# FM33FG0XXA register map
File version: 1.0
CPU: SC000 r1p0, little endian, MPU, no FPU, 3 interrupt priority bits
Registers are 32-bit, read-only, reset 0x0 unless marked. A register's access mark holds for its fields unless they carry their own. Offsets are from the block's base; [hi:lo] are bit positions; {n}, {i} and the like mark numbered series.

## CMU — CMU module information
Base 0x40002400
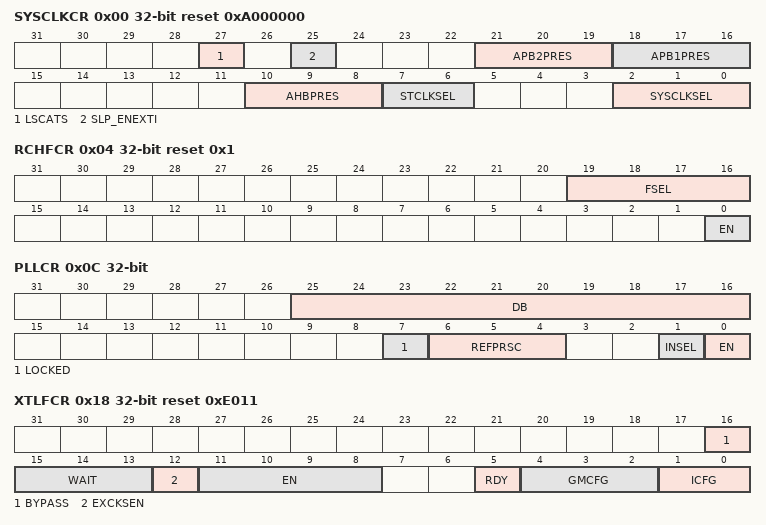
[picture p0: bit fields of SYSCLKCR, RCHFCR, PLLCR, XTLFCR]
0x00 SYSCLKCR rw reset 0xA000000 — System Clock Control Register
  [27] LSCATS — LSCATS field description
  [25] SLP_ENEXTI — SLP_ENEXTI field description
  [21:19] APB2PRES — APB2PRES field description
  [18:16] APB1PRES — APB1PRES field description
  [10:8] AHBPRES — AHBPRES field description
  [7:6] STCLKSEL — STCLKSEL field description
  [2:0] SYSCLKSEL — SYSCLKSEL field description
0x04 RCHFCR rw reset 0x1 — RCHF Control Register
  [19:16] FSEL — FSEL field description
  [0] EN — EN field description
0x08 RCHFTR rw — RCHF Trim Register
  [7:0] TRIM — TRIM field description
0x0C PLLCR access per field — PLL Control Register
  [25:16] DB rw — DB field description
  [7] LOCKED ro — LOCKED field description
  [6:4] REFPRSC rw — REFPRSC field description
  [1] INSEL rw — INSEL field description
  [0] EN rw — EN field description
0x14 RCLPTR rw — RCLP Trim Register
  [7:0] TRIM — TRIM field description
0x18 XTLFCR access per field reset 0xE011 — XTLF Control Register
  [16] BYPASS rw — BYPASS field description
  [15:13] WAIT rw — WAIT field description
  [12] EXCKSEN rw — EXCKSEN field description
  [11:8] EN rw — EN field description
  [5] RDY ro — RDY field description
  [4:2] GMCFG rw — GMCFG field description
  [1:0] ICFG rw — ICFG field description
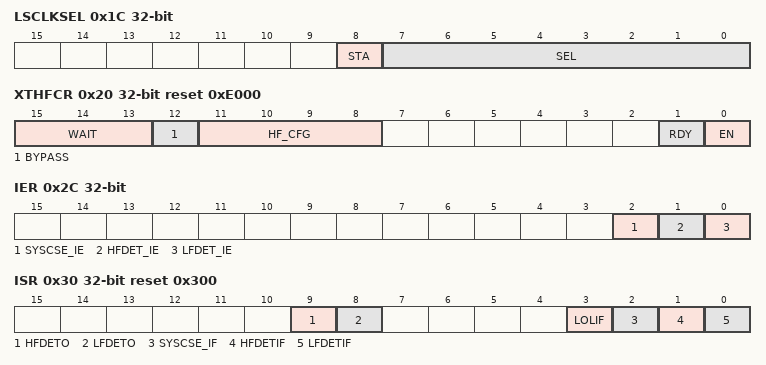
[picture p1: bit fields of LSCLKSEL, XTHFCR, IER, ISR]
0x1C LSCLKSEL access per field — LSCLK Select Register
  [8] STA ro — STA field description
  [7:0] SEL rw — SEL field description
0x20 XTHFCR access per field reset 0xE000 — XTHF Control Register
  [15:13] WAIT rw — WAIT field description
  [12] BYPASS rw — BYPASS field description
  [11:8] HF_CFG rw — HF_CFG field description
  [1] RDY ro — RDY field description
  [0] EN rw — EN field description
0x2C IER rw — Interrupt Enable Register
  [2] SYSCSE_IE — SYSCSE_IE field description
  [1] HFDET_IE — HFDET_IE field description
  [0] LFDET_IE — LFDET_IE field description
0x30 ISR access per field reset 0x300 — Interrupt Status Register
  [9] HFDETO ro — HFDETO field description
  [8] LFDETO ro — LFDETO field description
  [3] LOLIF rw — LOLIF field description
  [2] SYSCSE_IF rw — SYSCSE_IF field description
  [1] HFDETIF rw — HFDETIF field description
  [0] LFDETIF rw — LFDETIF field description
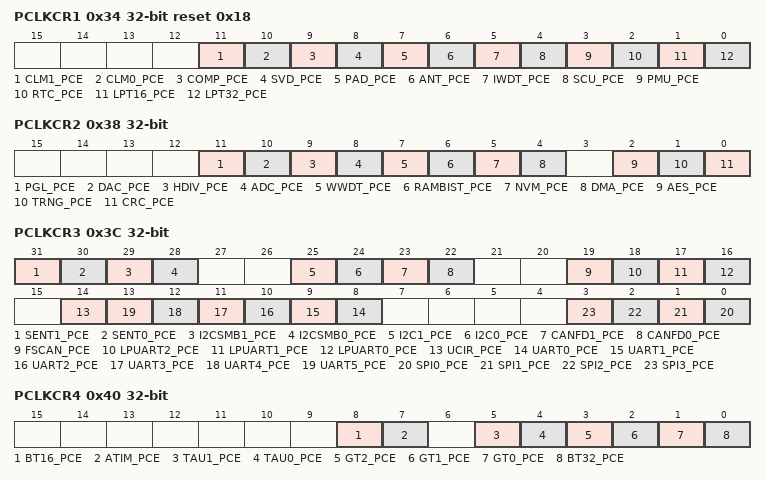
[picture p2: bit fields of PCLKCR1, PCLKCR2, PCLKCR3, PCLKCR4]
0x34 PCLKCR1 rw reset 0x18 — Peripheral bus Clock Control Register1
  [11] CLM1_PCE — CLM1_PCE field description
  [10] CLM0_PCE — CLM0_PCE field description
  [9] COMP_PCE — COMP_PCE field description
  [8] SVD_PCE — SVD_PCE field description
  [7] PAD_PCE — PAD_PCE field description
  [6] ANT_PCE — ANT_PCE field description
  [5] IWDT_PCE — IWDT_PCE field description
  [4] SCU_PCE — SCU_PCE field description
  [3] PMU_PCE — PMU_PCE field description
  [2] RTC_PCE — RTC_PCE field description
  [1] LPT16_PCE — LPT16_PCE field description
  [0] LPT32_PCE — LPT32_PCE field description
0x38 PCLKCR2 rw — Peripheral bus Clock Control Register2
  [11] PGL_PCE — PGL_PCE field description
  [10] DAC_PCE — DAC_PCE field description
  [9] HDIV_PCE — HDIV_PCE field description
  [8] ADC_PCE — ADC_PCE field description
  [7] WWDT_PCE — WWDT_PCE field description
  [6] RAMBIST_PCE — RAMBIST_PCE field description
  [5] NVM_PCE — NVM_PCE field description
  [4] DMA_PCE — DMA_PCE field description
  [2] AES_PCE — AES_PCE field description
  [1] TRNG_PCE — TRNG_PCE field description
  [0] CRC_PCE — CRC_PCE field description
0x3C PCLKCR3 rw — Peripheral bus Clock Control Register3
  [31] SENT1_PCE — SENT1_PCE field description
  [30] SENT0_PCE — SENT0_PCE field description
  [29] I2CSMB1_PCE — I2CSMB1_PCE field description
  [28] I2CSMB0_PCE — I2CSMB0_PCE field description
  [25] I2C1_PCE — I2C1_PCE field description
  [24] I2C0_PCE — I2C0_PCE field description
  [23] CANFD1_PCE — CANFD1_PCE field description
  [22] CANFD0_PCE — CANFD0_PCE field description
  [19] FSCAN_PCE — FSCAN_PCE field description
  [18] LPUART2_PCE — LPUART2_PCE field description
  [17] LPUART1_PCE — LPUART1_PCE field description
  [16] LPUART0_PCE — LPUART0_PCE field description
  [14] UCIR_PCE — UCIR_PCE field description
  [n+8] UART{n}_PCE (n=0..5) — UART{n}_PCE field description
  [n] SPI{n}_PCE (n=0..3) — SPI{n}_PCE field description
0x40 PCLKCR4 rw — Peripheral bus Clock Control Register4
  [8] BT16_PCE — BT16_PCE field description
  [7] ATIM_PCE — ATIM_PCE field description
  [5] TAU1_PCE — TAU1_PCE field description
  [4] TAU0_PCE — TAU0_PCE field description
  [3] GT2_PCE — GT2_PCE field description
  [2] GT1_PCE — GT1_PCE field description
  [1] GT0_PCE — GT0_PCE field description
  [0] BT32_PCE — BT32_PCE field description
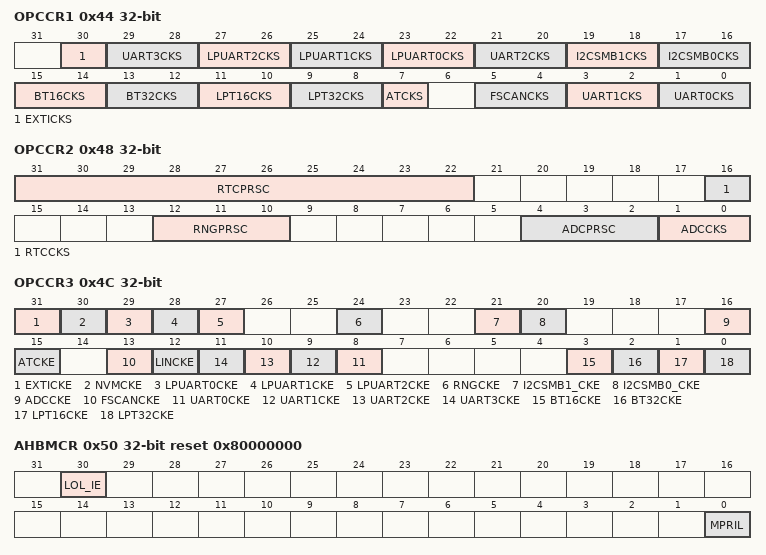
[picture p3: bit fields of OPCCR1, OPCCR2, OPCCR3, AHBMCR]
0x44 OPCCR1 rw — Peripheral Clock Config Register1
  [30] EXTICKS — EXTICKS field description
  [29:28] UART3CKS — UART3CKS field description
  [27:26] LPUART2CKS — LPUART2CKS field description
  [25:24] LPUART1CKS — LPUART1CKS field description
  [23:22] LPUART0CKS — LPUART0CKS field description
  [21:20] UART2CKS — UART2CKS field description
  [19:18] I2CSMB1CKS — I2CSMB1CKS field description
  [17:16] I2CSMB0CKS — I2CSMB0CKS field description
  [15:14] BT16CKS — BT16CKS field description
  [13:12] BT32CKS — BT32CKS field description
  [11:10] LPT16CKS — LPT16CKS field description
  [9:8] LPT32CKS — LPT32CKS field description
  [7] ATCKS — ATCKS field description
  [5:4] FSCANCKS — FSCANCKS field description
  [3:2] UART1CKS — UART1CKS field description
  [1:0] UART0CKS — UART0CKS field description
0x48 OPCCR2 rw — Peripheral Clock Config Register 2
  [31:22] RTCPRSC — RTCPRSC field description
  [16] RTCCKS — RTCCKS field description
  [12:10] RNGPRSC — RNGPRSC field description
  [4:2] ADCPRSC — ADCPRSC field description
  [1:0] ADCCKS — ADCCKS field description
0x4C OPCCR3 rw — Peripheral Clock Enable Register
  [31] EXTICKE — EXTICKE field description
  [30] NVMCKE — NVMCKE field description
  [29] LPUART0CKE — LPUART0CKE field description
  [28] LPUART1CKE — LPUART1CKE field description
  [27] LPUART2CKE — LPUART2CKE field description
  [24] RNGCKE — RNGCKE field description
  [21] I2CSMB1_CKE — I2CSMB1_CKE field description
  [20] I2CSMB0_CKE — I2CSMB0_CKE field description
  [16] ADCCKE — ADCCKE field description
  [15] ATCKE — ATCKE field description
  [13] FSCANCKE — FSCANCKE field description
  [12] LINCKE — LINCKE field description
  [n+8] UART{n}CKE (n=0..3) — UART{n}CKE field description
  [3] BT16CKE — BT16CKE field description
  [2] BT32CKE — BT32CKE field description
  [1] LPT16CKE — LPT16CKE field description
  [0] LPT32CKE — LPT32CKE field description
0x50 AHBMCR rw reset 0x80000000 — AHB Master Control Register
  [30] LOL_IE — LOL_IE field description
  [0] MPRIL — MPRIL field description
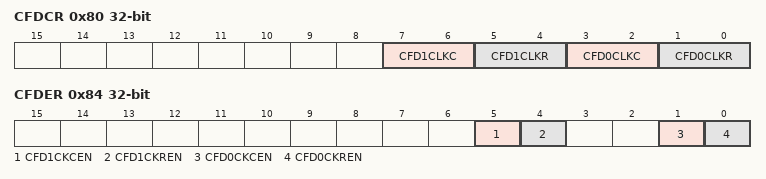
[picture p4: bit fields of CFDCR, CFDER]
0x80 CFDCR rw — CANFD Clock Config Register
  [7:6] CFD1CLKC — CFD1CLKC field description
  [5:4] CFD1CLKR — CFD1CLKR field description
  [3:2] CFD0CLKC — CFD0CLKC field description
  [1:0] CFD0CLKR — CFD0CLKR field description
0x84 CFDER rw — CANFD Clock Enable Register
  [5] CFD1CKCEN — CFD1CKCEN field description
  [4] CFD1CKREN — CFD1CKREN field description
  [1] CFD0CKCEN — CFD0CKCEN field description
  [0] CFD0CKREN — CFD0CKREN field description
